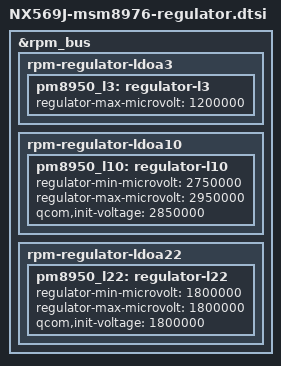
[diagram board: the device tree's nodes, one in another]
/*
 * Copyright (c) 2014-2016, The Linux Foundation. All rights reserved.
 *
 * This program is free software; you can redistribute it and/or modify
 * it under the terms of the GNU General Public License version 2 and
 * only version 2 as published by the Free Software Foundation.
 *
 * This program is distributed in the hope that it will be useful,
 * but WITHOUT ANY WARRANTY; without even the implied warranty of
 * MERCHANTABILITY or FITNESS FOR A PARTICULAR PURPOSE.  See the
 * GNU General Public License for more details.
 */

&rpm_bus {
	rpm-regulator-ldoa3 {
		pm8950_l3: regulator-l3 {
			regulator-max-microvolt = <1200000>;//ZTEMT: change by congshan from 1100000 to 1200000
		};
	};


	rpm-regulator-ldoa10 {
		pm8950_l10: regulator-l10 {
			regulator-min-microvolt = <2750000>;
			regulator-max-microvolt = <2950000>;
			qcom,init-voltage = <2850000>;
		};
	};


	rpm-regulator-ldoa22 {
		pm8950_l22: regulator-l22 {
			regulator-min-microvolt = <1800000>;
			regulator-max-microvolt = <1800000>;
			qcom,init-voltage = <1800000>;
		};
	};
};

